# MCXA156 register map
Vendor: nxp.com; File version: 1.0
CPU: CM33 r2p0, little endian, no MPU, FPU, VTOR, 3 interrupt priority bits
Registers are 32-bit, read-write, reset 0x0 unless marked. A register's access mark holds for its fields unless they carry their own. Offsets are from the block's base; [hi:lo] are bit positions; 'fields as' and 'values as' point back to an identical list.

## AOI0 — AOI
Base 0x40089000
Same registers: AOI1 0x40097000
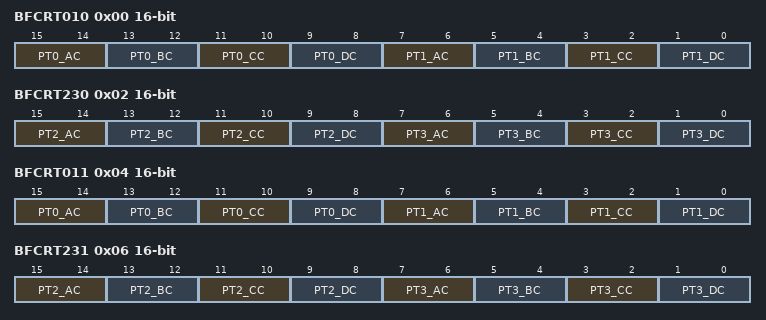
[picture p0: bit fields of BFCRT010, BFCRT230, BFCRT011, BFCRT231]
0x00 BFCRT010 16-bit — Boolean Function Term 0 and 1 Configuration for EVENT0
  [15:14] PT0_AC — Product Term 0, Input A Configuration
    0=FORCE_0 (Force input A to become 0); 1=PASS (Pass input A); 2=COMPLEMENT (Complement input A); 3=FORCE_1 (Force input A to become 1)
  [13:12] PT0_BC — Product Term 0, Input B Configuration
    0=FORCE_0 (Force input B to become 0); 1=PASS (Pass input B); 2=COMPLEMENT (Complement input B); 3=FORCE_1 (Force input B to become 1)
  [11:10] PT0_CC — Product Term 0, Input C Configuration
    0=FORCE_0 (Force input C to become 0); 1=PASS (Pass input C); 2=COMPLEMENT (Complement input C); 3=FORCE_1 (Force input C to become 1)
  [9:8] PT0_DC — Product Term 0, Input D Configuration
    0=FORCE_0 (Force input D to become 0); 1=PASS (Pass input D); 2=COMPLEMENT (Complement input D); 3=FORCE_1 (Force input D to become 1)
  [7:6] PT1_AC — Product Term 1, Input A Configuration
    values as PT0_AC
  [5:4] PT1_BC — Product Term 1, Input B Configuration
    values as PT0_BC
  [3:2] PT1_CC — Product Term 1, Input C Configuration
    values as PT0_CC
  [1:0] PT1_DC — Product Term 1, Input D Configuration
    values as PT0_DC
0x02 BFCRT230 16-bit — Boolean Function Term 2 and 3 Configuration for EVENT0
  [15:14] PT2_AC — Product Term 2, Input A Configuration
    values as BFCRT010.PT0_AC
  [13:12] PT2_BC — Product Term 2, Input B Configuration
    values as BFCRT010.PT0_BC
  [11:10] PT2_CC — Product Term 2, Input C Configuration
    values as BFCRT010.PT0_CC
  [9:8] PT2_DC — Product Term 2, Input D Configuration
    values as BFCRT010.PT0_DC
  [7:6] PT3_AC — Product Term 3, Input A Configuration
    0=FORCE_0 (Force input A to become 0); 1=PASS (Pass input A); 2=COMPLEMENT (Complement input A); 3=FORCE_1 (Force input to become 1)
  [5:4] PT3_BC — Product Term 3, Input B Configuration
    values as BFCRT010.PT0_BC
  [3:2] PT3_CC — Product Term 3, Input C Configuration
    values as BFCRT010.PT0_CC
  [1:0] PT3_DC — Product Term 3, Input D Configuration
    values as BFCRT010.PT0_DC
0x04 BFCRT011 16-bit — Boolean Function Term 0 and 1 Configuration for EVENT1
  fields as BFCRT010
0x06 BFCRT231 16-bit — Boolean Function Term 2 and 3 Configuration for EVENT1
  fields as BFCRT230
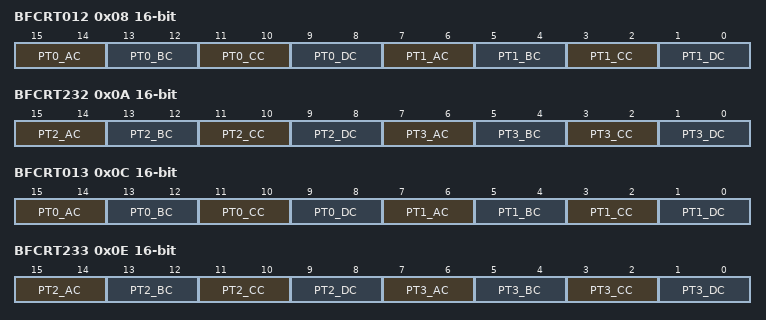
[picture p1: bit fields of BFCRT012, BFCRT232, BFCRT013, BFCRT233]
0x08 BFCRT012 16-bit — Boolean Function Term 0 and 1 Configuration for EVENT2
  fields as BFCRT010
0x0A BFCRT232 16-bit — Boolean Function Term 2 and 3 Configuration for EVENT2
  fields as BFCRT230
0x0C BFCRT013 16-bit — Boolean Function Term 0 and 1 Configuration for EVENT3
  fields as BFCRT010
0x0E BFCRT233 16-bit — Boolean Function Term 2 and 3 Configuration for EVENT3
  fields as BFCRT230

## CRC0 — CRC
Base 0x4008A000
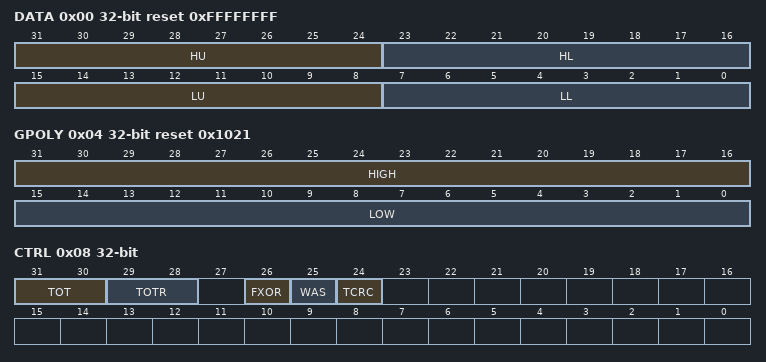
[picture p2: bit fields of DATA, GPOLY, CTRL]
0x00 DATA reset 0xFFFFFFFF
  [31:24] HU — Upper Part of High Byte
  [23:16] HL — Lower Part of High Byte
  [15:8] LU — Upper Part of Low Byte
  [7:0] LL — Lower Part of Low Byte
0x04 GPOLY reset 0x1021 — Polynomial
  [31:16] HIGH — High Half-Word
  [15:0] LOW — Low Half-Word
0x08 CTRL — Control
  [31:30] TOT — Transpose Type for Write
    0=NOTRNPS (No transposition); 1=BTS_TRNPS (Bits in bytes are transposed, but bytes are not transposed.); 2=BYTS_BTS_TRNPS (Both bits in bytes and bytes are transposed.); 3=BYTS_TRNPS (Only bytes are transposed, no bits in a byte are transposed.)
  [29:28] TOTR — Transpose Type for Read
    values as TOT
  [26] FXOR — Complement Read of CRC Data Register
    0=NOXOR (Disables XOR on reading data.); 1=INVERT (Inverts or complements the read value of the CRC Data.)
  [25] WAS — Write as Seed
    0=DATA (Data values); 1=SEED (Seed values)
  [24] TCRC
    0=B16 (16 bits); 1=B32 (32 bits)
